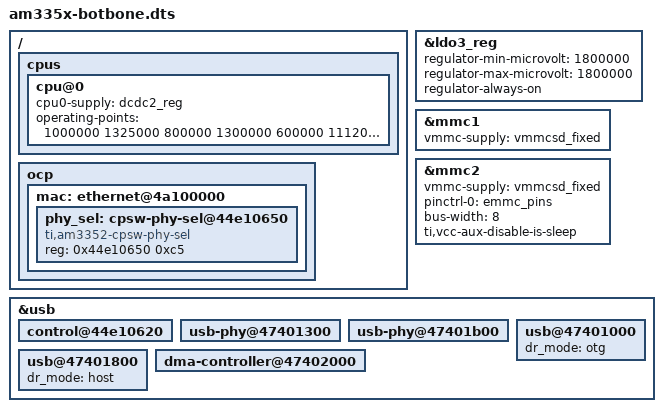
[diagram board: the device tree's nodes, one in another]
/*
 * Copyright (C) 2012 Texas Instruments Incorporated - http://www.ti.com/
 *
 * This program is free software; you can redistribute it and/or modify
 * it under the terms of the GNU General Public License version 2 as
 * published by the Free Software Foundation.
 */
/dts-v1/;

#include "am33xx.dtsi"
#include "am335x-botbone-common.dtsi"

&ldo3_reg {
	regulator-min-microvolt = <1800000>;
	regulator-max-microvolt = <1800000>;
	regulator-always-on;
};

&mmc1 {
	vmmc-supply = <&vmmcsd_fixed>;
};

&mmc2 {
	vmmc-supply = <&vmmcsd_fixed>;
	pinctrl-names = "default";
	pinctrl-0 = <&emmc_pins>;
	bus-width = <8>;
	status = "okay";
	ti,vcc-aux-disable-is-sleep;
};

&usb {
	status = "okay";

		control@44e10620 {
		status = "okay";
	};

	usb-phy@47401300 {
		status = "okay";
	};

	usb-phy@47401b00 {
		status = "okay";
	};

	usb@47401000 {
		status = "okay";
		dr_mode = "otg";
	};

	usb@47401800 {
		status = "okay";
		dr_mode = "host";
	};

	dma-controller@47402000  {
		status = "okay";
	};
};

/ {
	cpus {
		cpu@0 {
			cpu0-supply = <&dcdc2_reg>;
			/*
			 * To consider voltage drop between PMIC and SoC,
			 * tolerance value is reduced to 2% from 4% and
			 * voltage value is increased as a precaution.
			 */
			operating-points = <
				/* kHz    uV */
				1000000	1325000
				800000	1300000
				600000  1112000
				300000   969000
			>;
		};
	};

	ocp {
		mac: ethernet@4a100000 {
			phy_sel: cpsw-phy-sel@44e10650 {
				compatible = "ti,am3352-cpsw-phy-sel";
				reg= <0x44e10650 0xc5>;		/* RMII, RMII */
				reg-names = "gmii-sel";
			};			
		};
	};
};
